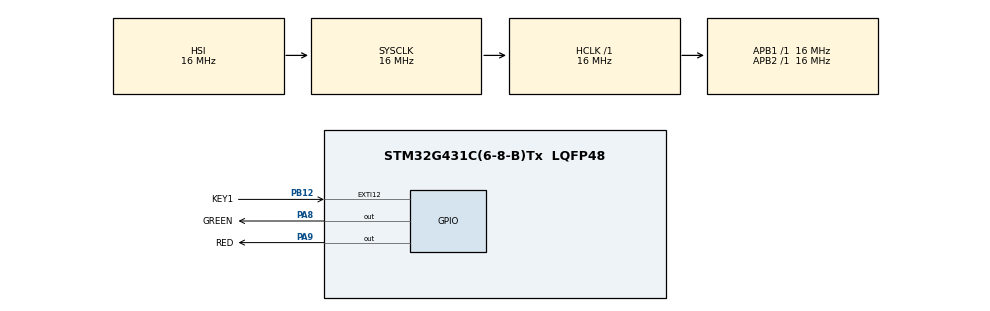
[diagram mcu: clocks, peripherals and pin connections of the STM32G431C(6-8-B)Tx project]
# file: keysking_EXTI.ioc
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Mcu.Family=STM32G4
Mcu.Name=STM32G431C(6-8-B)Tx
Mcu.Package=LQFP48
NVIC.EXTI15_10_IRQn=true\:15\:0\:true\:false\:true\:true\:true\:true
NVIC.PriorityGroup=NVIC_PRIORITYGROUP_4
PA13.Mode=Serial_Wire
PA13.Signal=SYS_JTMS-SWDIO
PA14.Mode=Serial_Wire
PA14.Signal=SYS_JTCK-SWCLK
PA8.GPIO_Label=GREEN
PA8.GPIO_PuPd=GPIO_PULLUP
PA8.PinState=GPIO_PIN_RESET
PA8.Signal=GPIO_Output
PA9.GPIO_Label=RED
PA9.GPIO_PuPd=GPIO_PULLUP
PA9.GPIO_Speed=GPIO_SPEED_FREQ_LOW
PA9.Signal=GPIO_Output
PB12.GPIO_Label=KEY1
PB12.GPIO_ModeDefaultEXTI=GPIO_MODE_IT_FALLING
PB12.GPIO_PuPd=GPIO_PULLUP
PB12.Signal=GPXTI12
ProjectManager.HeapSize=0x200
ProjectManager.StackSize=0x400
ProjectManager.TargetToolchain=CMake
RCC.AHBFreq_Value=16000000
RCC.APB1Freq_Value=16000000
RCC.APB1TimFreq_Value=16000000
RCC.APB2Freq_Value=16000000
RCC.APB2TimFreq_Value=16000000
RCC.CortexFreq_Value=16000000
RCC.EXTERNAL_CLOCK_VALUE=12288000
RCC.HCLKFreq_Value=16000000
RCC.HSE_VALUE=8000000
RCC.HSI48_VALUE=48000000
RCC.HSI_VALUE=16000000
RCC.LSE_VALUE=32768
RCC.SYSCLKFreq_VALUE=16000000
RCC.USBFreq_Value=64000000
RCC.VCOOutputFreq_Value=128000000
VP_SYS_VS_DBSignals.Mode=DisableDeadBatterySignals
board=custom

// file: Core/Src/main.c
/* USER CODE BEGIN Header */
/**
  ******************************************************************************
  * @file           : main.c
  * @brief          : Main program body
  ******************************************************************************
  * @attention
  *
  * Copyright (c) 2025 STMicroelectronics.
  * All rights reserved.
  *
  * This software is licensed under terms that can be found in the LICENSE file
  * in the root directory of this software component.
  * If no LICENSE file comes with this software, it is provided AS-IS.
  *
  ******************************************************************************
  */
/* USER CODE END Header */
#include "main.h"

/* USER CODE BEGIN PV */
// 按键消抖相关变量
#define DEBOUNCE_DELAY_MS 50 // 消抖时间，单位毫秒 (50ms is a good starting point)
uint32_t last_key1_press_time = 0; // 记录上次按键按下的时间戳
/* USER CODE END PV */

void SystemClock_Config(void);
static void MX_GPIO_Init(void);

int main(void)
{

  /* MCU Configuration--------------------------------------------------------*/

  /* Reset of all peripherals, Initializes the Flash interface and the Systick. */
  HAL_Init();

  /* Configure the system clock */
  SystemClock_Config();

  /* Initialize all configured peripherals */
  MX_GPIO_Init();

  /* Infinite loop */
  /* USER CODE BEGIN WHILE */
  while (1)
  {
    HAL_GPIO_WritePin(GREEN_GPIO_Port,GREEN_Pin,GPIO_PIN_RESET);
    HAL_Delay(1000);
    HAL_GPIO_WritePin(GREEN_GPIO_Port,GREEN_Pin,GPIO_PIN_SET);
    HAL_Delay(1000);

    /* USER CODE END WHILE */

  }
}

void SystemClock_Config(void)
{
  RCC_OscInitTypeDef RCC_OscInitStruct = {0};
  RCC_ClkInitTypeDef RCC_ClkInitStruct = {0};

  /** Configure the main internal regulator output voltage
  */
  HAL_PWREx_ControlVoltageScaling(PWR_REGULATOR_VOLTAGE_SCALE1);

  /** Initializes the RCC Oscillators according to the specified parameters
  * in the RCC_OscInitTypeDef structure.
  */
  RCC_OscInitStruct.OscillatorType = RCC_OSCILLATORTYPE_HSI;
  RCC_OscInitStruct.HSIState = RCC_HSI_ON;
  RCC_OscInitStruct.HSICalibrationValue = RCC_HSICALIBRATION_DEFAULT;
  RCC_OscInitStruct.PLL.PLLState = RCC_PLL_NONE;
  if (HAL_RCC_OscConfig(&RCC_OscInitStruct) != HAL_OK)
  {
    Error_Handler();
  }

  /** Initializes the CPU, AHB and APB buses clocks
  */
  RCC_ClkInitStruct.ClockType = RCC_CLOCKTYPE_HCLK|RCC_CLOCKTYPE_SYSCLK
                              |RCC_CLOCKTYPE_PCLK1|RCC_CLOCKTYPE_PCLK2;
  RCC_ClkInitStruct.SYSCLKSource = RCC_SYSCLKSOURCE_HSI;
  RCC_ClkInitStruct.AHBCLKDivider = RCC_SYSCLK_DIV1;
  RCC_ClkInitStruct.APB1CLKDivider = RCC_HCLK_DIV1;
  RCC_ClkInitStruct.APB2CLKDivider = RCC_HCLK_DIV1;

  if (HAL_RCC_ClockConfig(&RCC_ClkInitStruct, FLASH_LATENCY_0) != HAL_OK)
  {
    Error_Handler();
  }
}

static void MX_GPIO_Init(void)
{
  GPIO_InitTypeDef GPIO_InitStruct = {0};

  /* GPIO Ports Clock Enable */
  __HAL_RCC_GPIOB_CLK_ENABLE();
  __HAL_RCC_GPIOA_CLK_ENABLE();

  /*Configure GPIO pin Output Level */
  HAL_GPIO_WritePin(GPIOA, GREEN_Pin|RED_Pin, GPIO_PIN_RESET);

  /*Configure GPIO pin : KEY1_Pin */
  GPIO_InitStruct.Pin = KEY1_Pin;
  GPIO_InitStruct.Mode = GPIO_MODE_IT_FALLING;
  GPIO_InitStruct.Pull = GPIO_PULLUP;
  HAL_GPIO_Init(KEY1_GPIO_Port, &GPIO_InitStruct);

  /*Configure GPIO pins : GREEN_Pin RED_Pin */
  GPIO_InitStruct.Pin = GREEN_Pin|RED_Pin;
  GPIO_InitStruct.Mode = GPIO_MODE_OUTPUT_PP;
  GPIO_InitStruct.Pull = GPIO_PULLUP;
  GPIO_InitStruct.Speed = GPIO_SPEED_FREQ_LOW;
  HAL_GPIO_Init(GPIOA, &GPIO_InitStruct);

  /* EXTI interrupt init*/
  HAL_NVIC_SetPriority(EXTI15_10_IRQn, 15, 0);
  HAL_NVIC_EnableIRQ(EXTI15_10_IRQn);

}

/* USER CODE BEGIN 4 */
/**
  * @brief  EXTI line detection callbacks.
  * @param  GPIO_Pin: Specifies the port pin connected to corresponding EXTI line.
  * @retval None
  */
// void HAL_GPIO_EXTI_Callback(uint16_t GPIO_Pin)
// {
//   /* 检查是否是我们关心的KEY1引脚触发了中断 */
//   if(GPIO_Pin == KEY1_Pin)
//   {
//     /* 获取当前的系统时间 */
//     uint32_t current_time = HAL_GetTick();
//
//     /* 判断当前时间距离上次有效按键是否超过了设定的消抖时间 */
//     if((current_time - last_key1_press_time) > DEBOUNCE_DELAY_MS)
//     {
//       /* 如果超过了消抖时间，则认为是一次有效的按键 */
//
//       /* 1. 翻转LED的状态 */
//       HAL_GPIO_TogglePin(GREEN_GPIO_Port, GREEN_Pin);
//       // 修正：切换红色LED时应使用其对应的端口
//       HAL_GPIO_TogglePin(RED_GPIO_Port, RED_Pin);
//
//       /* 2. 更新上次按键时间为当前时间 */
//       last_key1_press_time = current_time;
//     }
//   }
// }
/* USER CODE END 4 */

void Error_Handler(void)
{
  __disable_irq();
  while (1)
  {
  }
}
